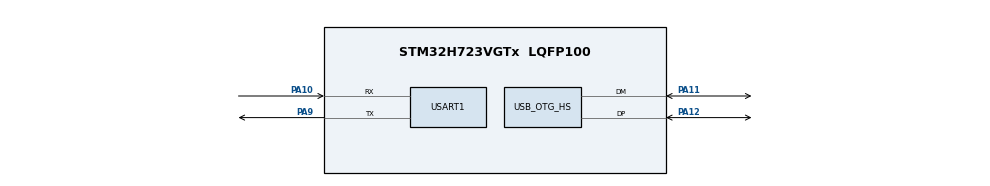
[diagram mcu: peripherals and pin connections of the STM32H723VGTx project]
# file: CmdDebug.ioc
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CORTEX_M7.default_mode_Activation=0
Dma.Request0=USART1_RX
Dma.USART1_RX.0.Direction=DMA_PERIPH_TO_MEMORY
Dma.USART1_RX.0.EventEnable=DISABLE
Dma.USART1_RX.0.FIFOMode=DMA_FIFOMODE_DISABLE
Dma.USART1_RX.0.Instance=DMA1_Stream0
Dma.USART1_RX.0.MemDataAlignment=DMA_MDATAALIGN_BYTE
Dma.USART1_RX.0.MemInc=DMA_MINC_ENABLE
Dma.USART1_RX.0.Mode=DMA_NORMAL
Dma.USART1_RX.0.PeriphDataAlignment=DMA_PDATAALIGN_BYTE
Dma.USART1_RX.0.PeriphInc=DMA_PINC_DISABLE
Dma.USART1_RX.0.Polarity=HAL_DMAMUX_REQ_GEN_RISING
Dma.USART1_RX.0.Priority=DMA_PRIORITY_LOW
Dma.USART1_RX.0.RequestNumber=1
Dma.USART1_RX.0.SignalID=NONE
Dma.USART1_RX.0.SyncEnable=DISABLE
Dma.USART1_RX.0.SyncPolarity=HAL_DMAMUX_SYNC_NO_EVENT
Dma.USART1_RX.0.SyncRequestNumber=1
Dma.USART1_RX.0.SyncSignalID=NONE
FREERTOS.INCLUDE_uxTaskGetStackHighWaterMark=1
FREERTOS.MEMORY_ALLOCATION=0
FREERTOS.Tasks01=defaultTask,0,128,StartDefaultTask,Default,NULL,Dynamic,NULL,NULL
FREERTOS.configTOTAL_HEAP_SIZE=32768
FREERTOS.configUSE_STATS_FORMATTING_FUNCTIONS=1
FREERTOS.configUSE_TRACE_FACILITY=1
Mcu.Family=STM32H7
Mcu.Name=STM32H723VGTx
Mcu.Package=LQFP100
NVIC.DMA1_Stream0_IRQn=true\:5\:0\:false\:false\:true\:true\:false\:true\:true
NVIC.OTG_HS_IRQn=true\:5\:0\:false\:false\:true\:true\:false\:true\:true
NVIC.PriorityGroup=NVIC_PRIORITYGROUP_4
NVIC.TIM17_IRQn=true\:15\:0\:false\:false\:true\:false\:false\:true\:true
NVIC.TimeBase=TIM17_IRQn
NVIC.TimeBaseIP=TIM17
NVIC.USART1_IRQn=true\:5\:0\:false\:false\:true\:true\:true\:true\:true
PA10.Mode=Asynchronous
PA10.Signal=USART1_RX
PA11.Mode=Device_Only_FS
PA11.Signal=USB_OTG_HS_DM
PA12.Mode=Device_Only_FS
PA12.Signal=USB_OTG_HS_DP
PA9.Mode=Asynchronous
PA9.Signal=USART1_TX
PD8.Signal=USART3_TX
PD9.Signal=USART3_RX
PH0-OSC_IN.Mode=HSE-External-Oscillator
PH0-OSC_IN.Signal=RCC_OSC_IN
PH1-OSC_OUT.Mode=HSE-External-Oscillator
PH1-OSC_OUT.Signal=RCC_OSC_OUT
ProjectManager.HeapSize=0x200
ProjectManager.StackSize=0x400
ProjectManager.TargetToolchain=MDK-ARM V5.32
RCC.ADCFreq_Value=50390625
RCC.APB1Freq_Value=137500000
RCC.APB2Freq_Value=137500000
RCC.APB3Freq_Value=137500000
RCC.APB4Freq_Value=137500000
RCC.CortexFreq_Value=550000000
RCC.D1PPRE=RCC_APB3_DIV2
RCC.D2PPRE1=RCC_APB1_DIV2
RCC.D2PPRE2=RCC_APB2_DIV2
RCC.D3PPRE=RCC_APB4_DIV2
RCC.DIVM1=2
RCC.DIVN1=44
RCC.DIVP1=1
RCC.HCLKFreq_Value=275000000
RCC.HPRE=RCC_HCLK_DIV2
RCC.PLLFRACN=0
RCC.PLLSourceVirtual=RCC_PLLSOURCE_HSE
RCC.SYSCLKFreq_VALUE=550000000
RCC.SYSCLKSource=RCC_SYSCLKSOURCE_PLLCLK
RCC.USBCLockSelection=RCC_USBCLKSOURCE_HSI48
RCC.USBFreq_Value=48000000
USART1.VirtualMode-Asynchronous=VM_ASYNC
USB_DEVICE.CLASS_NAME_HS=CDC
USB_DEVICE.VirtualMode=Cdc
USB_DEVICE.VirtualModeHS=Cdc_HS
USB_OTG_HS.VirtualMode-Device_Only_FS=Device_Only_FS
VP_FREERTOS_VS_CMSIS_V1.Mode=CMSIS_V1
VP_RTC_VS_RTC_Activate.Mode=RTC_Enabled
VP_RTC_VS_RTC_Calendar.Mode=RTC_Calendar
VP_SYS_VS_tim17.Mode=TIM17
VP_USB_DEVICE_VS_USB_DEVICE_CDC_HS.Mode=CDC_HS
board=custom

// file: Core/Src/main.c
/* USER CODE BEGIN Header */
/**
  ******************************************************************************
  * @file           : main.c
  * @brief          : Main program body
  ******************************************************************************
  * @attention
  *
  * Copyright (c) 2024 STMicroelectronics.
  * All rights reserved.
  *
  * This software is licensed under terms that can be found in the LICENSE file
  * in the root directory of this software component.
  * If no LICENSE file comes with this software, it is provided AS-IS.
  *
  ******************************************************************************
  */
/* USER CODE END Header */
#include "main.h"
#include "cmsis_os.h"
#include "dma.h"
#include "rtc.h"
#include "usart.h"
#include "usb_device.h"
#include "gpio.h"

/* USER CODE BEGIN Includes */
#include "usbd_cdc_if.h"
#include "global.h"
/* USER CODE END Includes */

/* USER CODE BEGIN PV */
uint8_t data[20];
uint32_t time = 0;
/* USER CODE END PV */

void SystemClock_Config(void);
void MX_FREERTOS_Init(void);

int main(void)
{

  /* MCU Configuration--------------------------------------------------------*/

  /* Reset of all peripherals, Initializes the Flash interface and the Systick. */
  HAL_Init();

  /* Configure the system clock */
  SystemClock_Config();

  /* Initialize all configured peripherals */
  MX_GPIO_Init();
  MX_DMA_Init();
  MX_RTC_Init();
  MX_USART1_UART_Init();
  /* USER CODE BEGIN 2 */
  start_task_init();
  /* USER CODE END 2 */

  /* Call init function for freertos objects (in cmsis_os2.c) */
  MX_FREERTOS_Init();

  /* Start scheduler */
  osKernelStart();

  /* We should never get here as control is now taken by the scheduler */

  /* Infinite loop */
  while (1)
  {

  }
}

void SystemClock_Config(void)
{
  RCC_OscInitTypeDef RCC_OscInitStruct = {0};
  RCC_ClkInitTypeDef RCC_ClkInitStruct = {0};

  /** Supply configuration update enable
  */
  HAL_PWREx_ConfigSupply(PWR_LDO_SUPPLY);

  /** Configure the main internal regulator output voltage
  */
  __HAL_PWR_VOLTAGESCALING_CONFIG(PWR_REGULATOR_VOLTAGE_SCALE0);

  while(!__HAL_PWR_GET_FLAG(PWR_FLAG_VOSRDY)) {}

  /** Initializes the RCC Oscillators according to the specified parameters
  * in the RCC_OscInitTypeDef structure.
  */
  RCC_OscInitStruct.OscillatorType = RCC_OSCILLATORTYPE_HSI48|RCC_OSCILLATORTYPE_LSI
                              |RCC_OSCILLATORTYPE_HSE;
  RCC_OscInitStruct.HSEState = RCC_HSE_ON;
  RCC_OscInitStruct.LSIState = RCC_LSI_ON;
  RCC_OscInitStruct.HSI48State = RCC_HSI48_ON;
  RCC_OscInitStruct.PLL.PLLState = RCC_PLL_ON;
  RCC_OscInitStruct.PLL.PLLSource = RCC_PLLSOURCE_HSE;
  RCC_OscInitStruct.PLL.PLLM = 2;
  RCC_OscInitStruct.PLL.PLLN = 44;
  RCC_OscInitStruct.PLL.PLLP = 1;
  RCC_OscInitStruct.PLL.PLLQ = 2;
  RCC_OscInitStruct.PLL.PLLR = 2;
  RCC_OscInitStruct.PLL.PLLRGE = RCC_PLL1VCIRANGE_3;
  RCC_OscInitStruct.PLL.PLLVCOSEL = RCC_PLL1VCOWIDE;
  RCC_OscInitStruct.PLL.PLLFRACN = 0;
  if (HAL_RCC_OscConfig(&RCC_OscInitStruct) != HAL_OK)
  {
    Error_Handler();
  }

  /** Initializes the CPU, AHB and APB buses clocks
  */
  RCC_ClkInitStruct.ClockType = RCC_CLOCKTYPE_HCLK|RCC_CLOCKTYPE_SYSCLK
                              |RCC_CLOCKTYPE_PCLK1|RCC_CLOCKTYPE_PCLK2
                              |RCC_CLOCKTYPE_D3PCLK1|RCC_CLOCKTYPE_D1PCLK1;
  RCC_ClkInitStruct.SYSCLKSource = RCC_SYSCLKSOURCE_PLLCLK;
  RCC_ClkInitStruct.SYSCLKDivider = RCC_SYSCLK_DIV1;
  RCC_ClkInitStruct.AHBCLKDivider = RCC_HCLK_DIV2;
  RCC_ClkInitStruct.APB3CLKDivider = RCC_APB3_DIV2;
  RCC_ClkInitStruct.APB1CLKDivider = RCC_APB1_DIV2;
  RCC_ClkInitStruct.APB2CLKDivider = RCC_APB2_DIV2;
  RCC_ClkInitStruct.APB4CLKDivider = RCC_APB4_DIV2;

  if (HAL_RCC_ClockConfig(&RCC_ClkInitStruct, FLASH_LATENCY_3) != HAL_OK)
  {
    Error_Handler();
  }
}

void HAL_TIM_PeriodElapsedCallback(TIM_HandleTypeDef *htim)
{
  if (htim->Instance == TIM17) {
    HAL_IncTick();
	rtc_ms++;
  }
}

void Error_Handler(void)
{
  __disable_irq();
  while (1)
  {
  }
}

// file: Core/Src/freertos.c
/* USER CODE BEGIN Header */
/**
  ******************************************************************************
  * File Name          : freertos.c
  * Description        : Code for freertos applications
  ******************************************************************************
  * @attention
  *
  * Copyright (c) 2024 STMicroelectronics.
  * All rights reserved.
  *
  * This software is licensed under terms that can be found in the LICENSE file
  * in the root directory of this software component.
  * If no LICENSE file comes with this software, it is provided AS-IS.
  *
  ******************************************************************************
  */
/* USER CODE END Header */

#include "FreeRTOS.h"
#include "task.h"
#include "main.h"
#include "cmsis_os.h"

osThreadId defaultTaskHandle;

void StartDefaultTask(void const * argument);

extern void MX_USB_DEVICE_Init(void);
void MX_FREERTOS_Init(void); /* (MISRA C 2004 rule 8.1) */

void MX_FREERTOS_Init(void) {

  /* Create the thread(s) */
  /* definition and creation of defaultTask */
  osThreadDef(defaultTask, StartDefaultTask, osPriorityNormal, 0, 128);
  defaultTaskHandle = osThreadCreate(osThread(defaultTask), NULL);

}

void StartDefaultTask(void const * argument)
{
  /* init code for USB_DEVICE */
  MX_USB_DEVICE_Init();
  for(;;)
  {
    osDelay(1);
  }
}
